AUTOSAR XML (schema 4-2-2)
package /DBC_SysDesc_Can_Network/Pkg_Cluster
  can cluster Can_NCluster: baudrate=500000, protocol-name=CAN
    can physical channel Can_NCluster_Channel: comm-connectors=Conn_CANNODE_0_BMS
      frame TMR_3: id 0x328, to BMS, frame-length=8, can-addressing-mode=STANDARD, can-frame-rx-behavior=ANY
        carries pdu TMR_3: packing-byte-order=big-endian, start-position=7, update-indication-bit-position=-1
        pdu TMR_3: length=8, transmission-mode-false-timing=cyclic-timing={time-offset=0.0, time-period=0.05}, transmission-mode-true-timing=cyclic-timing={time-offset=0.0, time-period=0.05}
          transmission-mode-conditions:
            {data-filter={data-filter-type=NEW-IS-WITHIN, max=1021, min=0, offset=0}, i-signal-in-i-pdu=TMR_VoltageHV}
            {data-filter={data-filter-type=NEW-IS-WITHIN, max=2044, min=0}, i-signal-in-i-pdu=TMR_CurrentHV}
          signal TMR_VoltageHV: start 12, 10 bit, big-endian, init-value=0, base-type=uint16, compu {raw=phys for phys 0..1021; unit V}, update-indication-bit-position=-1, to BMS  # HV voltage at the DC/AC converter"
          signal TMR_CurrentHV: start 7, 11 bit, big-endian, init-value=1023, base-type=uint16, compu {raw=phys+1023 for phys -1023..1021; unit Ampere}, update-indication-bit-position=-1, to BMS  # HV current at the DC/AC converter"
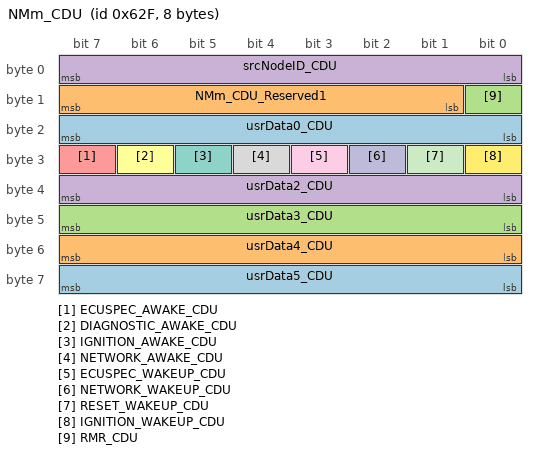
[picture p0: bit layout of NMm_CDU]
      frame NMm_CDU: id 0x62F, to BMS, frame-length=8, can-addressing-mode=STANDARD, can-frame-rx-behavior=ANY
        carries pdu NMm_CDU: packing-byte-order=big-endian, start-position=7, update-indication-bit-position=-1
        nm pdu NMm_CDU: length=8, nm-data-information=false, nm-vote-information=false
          signal usrData5_CDU: start 63, 8 bit, big-endian, init-value=0, base-type=uint8, compu {raw=phys for phys 0..255}, update-indication-bit-position=-1, to BMS
          signal usrData4_CDU: start 55, 8 bit, big-endian, init-value=0, base-type=uint8, compu {raw=phys for phys 0..255}, update-indication-bit-position=-1, to BMS
          signal usrData3_CDU: start 47, 8 bit, big-endian, init-value=0, base-type=uint8, compu {raw=phys for phys 0..255}, update-indication-bit-position=-1, to BMS
          signal usrData2_CDU: start 39, 8 bit, big-endian, init-value=0, base-type=uint8, compu {raw=phys for phys 0..255}, update-indication-bit-position=-1, to BMS
          signal ECUSPEC_AWAKE_CDU: start 31, 1 bit, big-endian, init-value=0, base-type=uint8, compu {raw=phys for phys 0..1, 0=INACTIVE, 1=ACTIVE}, update-indication-bit-position=-1, to BMS  # ECU keeps the network awake for ECU-define reasons for which communication is needed"
          signal DIAGNOSTIC_AWAKE_CDU: start 30, 1 bit, big-endian, init-value=0, base-type=uint8, compu {raw=phys for phys 0..1, 0=INACTIVE, 1=ACTIVE}, update-indication-bit-position=-1, to BMS  # ECU needs communication for diagnostic purpose and keeps network awake."
          signal IGNITION_AWAKE_CDU: start 29, 1 bit, big-endian, init-value=0, base-type=uint8, compu {raw=phys for phys 0..1, 0=INACTIVE, 1=ACTIVE}, update-indication-bit-position=-1, to BMS  # ECU can?t release communication because ignition (KL15) is turn on, or KLR is turned on"
          signal NETWORK_AWAKE_CDU: start 28, 1 bit, big-endian, init-value=0, base-type=uint8, compu {raw=phys for phys 0..1, 0=INACTIVE, 1=ACTIVE}, update-indication-bit-position=-1, to BMS  # ECU keeps the network awake due to the CAN message received from the network"
          signal ECUSPEC_WAKEUP_CDU: start 27, 1 bit, big-endian, init-value=0, base-type=uint8, compu {raw=phys for phys 0..1, 0=INACTIVE, 1=ACTIVE}, update-indication-bit-position=-1, to BMS  # ECU was in ??power off??, ??Bus Sleep??, ??Pre-pare Bus Sleep?? or ??Ready Sleep?? mode or ??awake?? and re-started by ECU specific reason (e.g. pressed Button, timer, etc.)"
          signal NETWORK_WAKEUP_CDU: start 26, 1 bit, big-endian, init-value=0, base-type=uint8, compu {raw=phys for phys 0..1, 0=INACTIVE, 1=ACTIVE}, update-indication-bit-position=-1, to BMS  # ECU was in ??Power off??, ??Bus Sleep??, ??Pre-pare Bus Sleep?? or ??Ready Sleep?? Mode and then re-started by a network communication."
          signal RESET_WAKEUP_CDU: start 25, 1 bit, big-endian, init-value=0, base-type=uint8, compu {raw=phys for phys 0..1, 0=INACTIVE, 1=ACTIVE}, update-indication-bit-position=-1, to BMS  # If ECU was already awake, in ??Prepare Bus Sleep?? or ??Ready Sleep?? mode and re-started by an internal or an external reset."
          signal IGNITION_WAKEUP_CDU: start 24, 1 bit, big-endian, init-value=0, base-type=uint8, compu {raw=phys for phys 0..1, 0=INACTIVE, 1=ACTIVE}, update-indication-bit-position=-1, to BMS  # ECU was ??power off?? or ??Bus sleep?? mode and started by ignition switch"
          signal usrData0_CDU: start 23, 8 bit, big-endian, init-value=0, base-type=uint8, compu-method=CompuMethod_usrData0_CDU, update-indication-bit-position=-1, to BMS
          signal NMm_CDU_Reserved1: start 15, 7 bit, big-endian, init-value=0, base-type=uint8, compu {raw=phys for phys 0..127}, update-indication-bit-position=-1, to BMS
          signal RMR_CDU: start 8, 1 bit, big-endian, init-value=0, base-type=uint8, compu {raw=phys for phys 0..1, 0=INACTIVE, 1=ACTIVE}, update-indication-bit-position=-1, to BMS  # If set to 1 to force the network management of all other nodes on the bus into the re-peat message state."
          signal srcNodeID_CDU: start 7, 8 bit, big-endian, init-value=2, base-type=uint8, compu {raw=phys for phys 0..255}, update-indication-bit-position=-1, to BMS
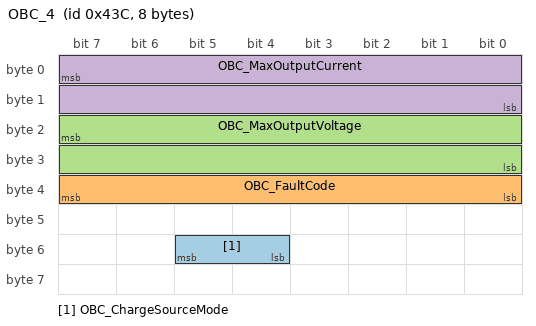
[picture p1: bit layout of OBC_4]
      frame OBC_4: id 0x43C, to BMS, frame-length=8, can-addressing-mode=STANDARD, can-frame-rx-behavior=ANY
        carries pdu OBC_4: packing-byte-order=big-endian, start-position=7, update-indication-bit-position=-1
        pdu OBC_4: length=8, transmission-mode-false-timing=cyclic-timing={time-offset=0.0, time-period=0.1}, transmission-mode-true-timing=cyclic-timing={time-offset=0.0, time-period=0.1}
          transmission-mode-conditions:
            {data-filter={data-filter-type=ALWAYS, max=0, min=0, offset=0}, i-signal-in-i-pdu=OBC_ChargeSourceMode}
            {data-filter={data-filter-type=ALWAYS, max=255, min=0, offset=0}, i-signal-in-i-pdu=OBC_FaultCode}
            {data-filter={data-filter-type=NEW-IS-WITHIN, max=20000, min=0, offset=0}, i-signal-in-i-pdu=OBC_MaxOutputVoltage}
            {data-filter={data-filter-type=NEW-IS-WITHIN, max=8000, min=0, offset=0}, i-signal-in-i-pdu=OBC_MaxOutputCurrent}
          signal OBC_ChargeSourceMode: start 53, 2 bit, big-endian, init-value=0, base-type=uint8, compu-method=CompuMethod_OBC_ChargeSourceMode, update-indication-bit-position=-1, to BMS  # Charge Source Mode"
          signal OBC_FaultCode: start 39, 8 bit, big-endian, init-value=0, base-type=uint8, compu {raw=phys for phys 0..255}, update-indication-bit-position=-1, to BMS  # OBC fault matrix"
          signal OBC_MaxOutputVoltage: start 23, 16 bit, big-endian, init-value=0, base-type=uint16, compu {raw=phys*20 for phys 0..1000; unit V}, update-indication-bit-position=-1, to BMS  # OBC maximum output current"
          signal OBC_MaxOutputCurrent: start 7, 16 bit, big-endian, init-value=0, base-type=uint16, compu {raw=phys*20 for phys 0..400; unit Ampere}, update-indication-bit-position=-1, to BMS  # OBC maximum output voltage"
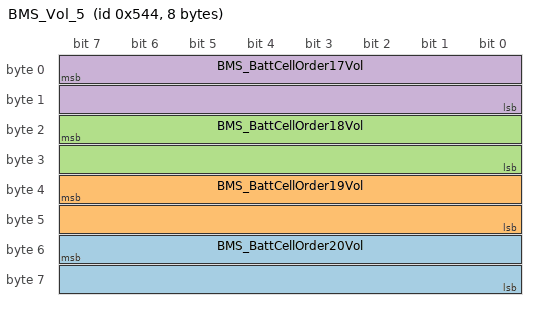
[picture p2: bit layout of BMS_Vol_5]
      frame BMS_Vol_5: id 0x544, from BMS, frame-length=8, can-addressing-mode=STANDARD
        carries pdu BMS_Vol_5: packing-byte-order=big-endian, start-position=7, update-indication-bit-position=-1
        pdu BMS_Vol_5: length=8, transmission-mode-false-timing=cyclic-timing={time-offset=0.0, time-period=1.0}, transmission-mode-true-timing=cyclic-timing={time-offset=0.0, time-period=1.0}
          transmission-mode-conditions:
            {data-filter={data-filter-type=NEW-IS-WITHIN, max=5000, min=0, offset=0}, i-signal-in-i-pdu=BMS_BattCellOrder20Vol}
            {data-filter={data-filter-type=NEW-IS-WITHIN, max=5000, min=0, offset=0}, i-signal-in-i-pdu=BMS_BattCellOrder19Vol}
            {data-filter={data-filter-type=NEW-IS-WITHIN, max=5000, min=0, offset=0}, i-signal-in-i-pdu=BMS_BattCellOrder18Vol}
            {data-filter={data-filter-type=NEW-IS-WITHIN, max=5000, min=0, offset=0}, i-signal-in-i-pdu=BMS_BattCellOrder17Vol}
          signal BMS_BattCellOrder20Vol: start 55, 16 bit, big-endian, init-value=0, base-type=uint16, compu {raw=phys for phys 0..5000; unit mV}, update-indication-bit-position=-1  # Battery Cell voltage Order20"
          signal BMS_BattCellOrder19Vol: start 39, 16 bit, big-endian, init-value=0, base-type=uint16, compu {raw=phys for phys 0..5000; unit mV}, update-indication-bit-position=-1  # Battery Cell voltage Order19"
          signal BMS_BattCellOrder18Vol: start 23, 16 bit, big-endian, init-value=0, base-type=uint16, compu {raw=phys for phys 0..5000; unit mV}, update-indication-bit-position=-1  # Battery Cell voltage Order18"
          signal BMS_BattCellOrder17Vol: start 7, 16 bit, big-endian, init-value=0, base-type=uint16, compu {raw=phys for phys 0..5000; unit mV}, update-indication-bit-position=-1  # Battery Cell voltage Order17"
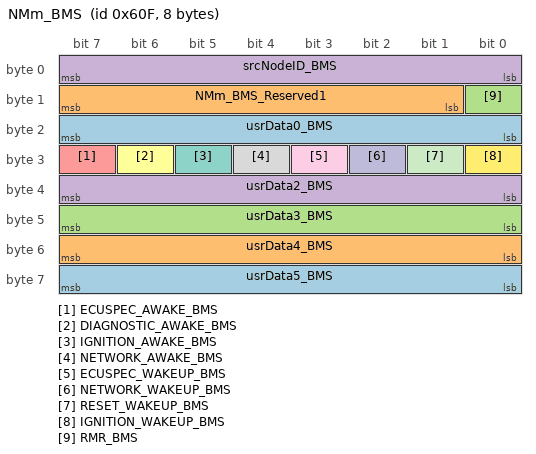
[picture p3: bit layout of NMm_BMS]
      frame NMm_BMS: id 0x60F, from BMS, frame-length=8, can-addressing-mode=STANDARD
        carries pdu NMm_BMS: packing-byte-order=big-endian, start-position=7, update-indication-bit-position=-1
        nm pdu NMm_BMS: length=8, nm-data-information=false, nm-vote-information=false
          signal usrData5_BMS: start 63, 8 bit, big-endian, init-value=0, base-type=uint8, compu {raw=phys for phys 0..255}, update-indication-bit-position=-1
          signal usrData4_BMS: start 55, 8 bit, big-endian, init-value=0, base-type=uint8, compu {raw=phys for phys 0..255}, update-indication-bit-position=-1
          signal usrData3_BMS: start 47, 8 bit, big-endian, init-value=0, base-type=uint8, compu {raw=phys for phys 0..255}, update-indication-bit-position=-1
          signal usrData2_BMS: start 39, 8 bit, big-endian, init-value=0, base-type=uint8, compu {raw=phys for phys 0..255}, update-indication-bit-position=-1
          signal ECUSPEC_AWAKE_BMS: start 31, 1 bit, big-endian, init-value=0, base-type=uint8, compu {raw=phys for phys 0..1, 0=INACTIVE, 1=ACTIVE}, update-indication-bit-position=-1  # ECU keeps the network awake for ECU-define reasons for which communication is needed"
          signal DIAGNOSTIC_AWAKE_BMS: start 30, 1 bit, big-endian, init-value=0, base-type=uint8, compu {raw=phys for phys 0..1, 0=INACTIVE, 1=ACTIVE}, update-indication-bit-position=-1  # ECU needs communication for diagnostic purpose and keeps network awake."
          signal IGNITION_AWAKE_BMS: start 29, 1 bit, big-endian, init-value=0, base-type=uint8, compu {raw=phys for phys 0..1, 0=INACTIVE, 1=ACTIVE}, update-indication-bit-position=-1  # ECU can?t release communication because ignition (KL15) is turn on, or KLR is turned on"
          signal NETWORK_AWAKE_BMS: start 28, 1 bit, big-endian, init-value=0, base-type=uint8, compu {raw=phys for phys 0..1, 0=INACTIVE, 1=ACTIVE}, update-indication-bit-position=-1  # ECU keeps the network awake due to the CAN message received from the network"
          signal ECUSPEC_WAKEUP_BMS: start 27, 1 bit, big-endian, init-value=0, base-type=uint8, compu {raw=phys for phys 0..1, 0=INACTIVE, 1=ACTIVE}, update-indication-bit-position=-1  # ECU was in ??power off??, ??Bus Sleep??, ??Pre-pare Bus Sleep?? or ??Ready Sleep?? mode or ??awake?? and re-started by ECU specific reason (e.g. pressed Button, timer, etc.)"
          signal NETWORK_WAKEUP_BMS: start 26, 1 bit, big-endian, init-value=0, base-type=uint8, compu {raw=phys for phys 0..1, 0=INACTIVE, 1=ACTIVE}, update-indication-bit-position=-1  # ECU was in ??Power off??, ??Bus Sleep??, ??Pre-pare Bus Sleep?? or ??Ready Sleep?? Mode and then re-started by a network communication."
          signal RESET_WAKEUP_BMS: start 25, 1 bit, big-endian, init-value=0, base-type=uint8, compu {raw=phys for phys 0..1, 0=INACTIVE, 1=ACTIVE}, update-indication-bit-position=-1  # If ECU was already awake, in ??Prepare Bus Sleep?? or ??Ready Sleep?? mode and re-started by an internal or an external reset."
          signal IGNITION_WAKEUP_BMS: start 24, 1 bit, big-endian, init-value=0, base-type=uint8, compu {raw=phys for phys 0..1, 0=INACTIVE, 1=ACTIVE}, update-indication-bit-position=-1  # ECU was ??power off?? or ??Bus sleep?? mode and started by ignition switch"
          signal usrData0_BMS: start 23, 8 bit, big-endian, init-value=0, base-type=uint8, compu-method=CompuMethod_usrData0_BMS, update-indication-bit-position=-1
          signal NMm_BMS_Reserved1: start 15, 7 bit, big-endian, init-value=0, base-type=uint8, compu {raw=phys for phys 0..127}, update-indication-bit-position=-1
          signal RMR_BMS: start 8, 1 bit, big-endian, init-value=0, base-type=uint8, compu {raw=phys for phys 0..1, 0=INACTIVE, 1=ACTIVE}, update-indication-bit-position=-1  # If set to 1 to force the network management of all other nodes on the bus into the re-peat message state."
          signal srcNodeID_BMS: start 7, 8 bit, big-endian, init-value=2, base-type=uint8, compu {raw=phys for phys 0..255}, update-indication-bit-position=-1
package /DBC_SysDesc_Can_Network/Pkg_Nm
  nm config NmConfig_0
    can nm cluster CanNmCluster_0: communication-cluster=Can_NCluster, nm-channel-id=1, nm-channel-sleep-master=false, nm-synchronizing-network=false, nm-busload-reduction-active=false, nm-car-wake-up-filter-enabled=false, nm-car-wake-up-rx-enabled=false, nm-channel-active=false
      can nm node CanNmMode_BMS_CANNODE_0: controller=CANNODE_0, nm-if-ecu=NmEcu_BMS, nm-node-id=1, nm-passive-mode-enabled=false, rx-nm-pdu=NMm_CDU, tx-nm-pdu=NMm_BMS, nm-range-config={lower-can-id=1551, upper-can-id=1583}
    nm-if-ecus:
      nm ecu NmEcu_BMS:
        bus-specific-nm-ecu=can-nm-ecu=nm-repeat-msg-indication-enabled=false
        ecu-instance=BMS
        nm-bus-synchronization-enabled=false
        nm-com-control-enabled=false
        nm-coordinator={index=0, nm-active-coordinator=true, nm-node=CanNmMode_BMS_CANNODE_0, nm-shutdown-delay-timer=0.0}
        nm-multiple-channels-enabled=false
        nm-node-detection-enabled=false
        nm-node-id-enabled=false
        nm-passive-mode-enabled=false
        nm-pdu-rx-indication-enabled=false
        nm-remote-sleep-ind-enabled=false
        nm-repeat-msg-ind-enabled=false
        nm-state-change-ind-enabled=false
        nm-user-data-enabled=false
package /DBC_SysDesc_Can_Network/Pkg_Ecu
  ecu instance BMS: com-configuration-gw-time-base=0.005, com-configuration-rx-time-base=0.01, com-configuration-tx-time-base=0.01, sleep-mode-supported=false, wake-up-over-bus-supported=false
    can communication controller CANNODE_0: can-controller-attributes=can-controller-configuration={prop-seg=2, sync-jump-width=1, time-seg-1=12, time-seg-2=5}
    can communication connector Conn_CANNODE_0_BMS: comm-controller=CANNODE_0
package /DBC_SysDesc_Can_Network/Pkg_CompuMethod
  compu method CompuMethod_usrData0_BMS: raw=phys for phys 0..255, 230=NOTUSED, 231=NOTUSED, 110=NOTUSED, 232=NOTUSED, 111=NOTUSED, 233=NOTUSED, 112=NOTUSED, 234=NOTUSED, 113=NOTUSED, 235=NOTUSED, 114=NOTUSED, 236=NOTUSED, 115=NOTUSED, 237=NOTUSED, 116=NOTUSED, 238=NOTUSED, 117=NOTUSED, 239=NOTUSED, 118=NOTUSED, 119=NOTUSED, 10..19=NOTUSED, 240=NOTUSED, 241=NOTUSED, 120=NOTUSED, 242=NOTUSED, 121=NOTUSED, 0=USERDATAFORCURRENTVEHICLE, 243=NOTUSED, 122=NOTUSED, 1=NOTUSED, 244=NOTUSED, 123=NOTUSED, 2=NOTUSED, 245=NOTUSED, 124=NOTUSED, 3=NOTUSED, 246=NOTUSED, 125=NOTUSED, 4=NOTUSED, 247=NOTUSED, 126=NOTUSED, 5=NOTUSED, 248=NOTUSED, 127=NOTUSED, 6=NOTUSED, 249=NOTUSED, 128=NOTUSED, 7=NOTUSED, 129=NOTUSED, 8=NOTUSED, 9=NOTUSED, 20..29=NOTUSED, 250=NOTUSED, 251=NOTUSED, 130=NOTUSED, 252=NOTUSED, 131=NOTUSED, 253=NOTUSED, 132=NOTUSED, 254=NOTUSED, 133=NOTUSED, 134=NOTUSED, 255=USERDATANOTUSED, 135..139=NOTUSED, 30..39=NOTUSED, 140..149=NOTUSED, 40..49=NOTUSED, 150..159=NOTUSED, 50..59=NOTUSED, 160..169=NOTUSED, 60..69=NOTUSED, 170..179=NOTUSED, 70..79=NOTUSED, 180..189=NOTUSED, 80..89=NOTUSED, 190..199=NOTUSED, 90..99=NOTUSED, 200..221=NOTUSED, 100=NOTUSED, 222=NOTUSED, 101=NOTUSED, 223=NOTUSED, 102=NOTUSED, 224=NOTUSED, 103=NOTUSED, 225=NOTUSED, 104=NOTUSED, 226=NOTUSED, 105=NOTUSED, 227=NOTUSED, 106=NOTUSED, 228=NOTUSED, 107=NOTUSED, 229=NOTUSED, 108=NOTUSED, 109=NOTUSED
  compu method CompuMethod_usrData0_CDU: raw=phys for phys 0..255, 230=NOTUSED, 231=NOTUSED, 110=NOTUSED, 232=NOTUSED, 111=NOTUSED, 233=NOTUSED, 112=NOTUSED, 234=NOTUSED, 113=NOTUSED, 235=NOTUSED, 114=NOTUSED, 236=NOTUSED, 115=NOTUSED, 237=NOTUSED, 116=NOTUSED, 238=NOTUSED, 117=NOTUSED, 239=NOTUSED, 118=NOTUSED, 119=NOTUSED, 10..19=NOTUSED, 240=NOTUSED, 241=NOTUSED, 120=NOTUSED, 242=NOTUSED, 121=NOTUSED, 0=USERDATAFORCURRENTVEHICLE, 243=NOTUSED, 122=NOTUSED, 1=NOTUSED, 244=NOTUSED, 123=NOTUSED, 2=NOTUSED, 245=NOTUSED, 124=NOTUSED, 3=NOTUSED, 246=NOTUSED, 125=NOTUSED, 4=NOTUSED, 247=NOTUSED, 126=NOTUSED, 5=NOTUSED, 248=NOTUSED, 127=NOTUSED, 6=NOTUSED, 249=NOTUSED, 128=NOTUSED, 7=NOTUSED, 129=NOTUSED, 8=NOTUSED, 9=NOTUSED, 20..29=NOTUSED, 250=NOTUSED, 251=NOTUSED, 130=NOTUSED, 252=NOTUSED, 131=NOTUSED, 253=NOTUSED, 132=NOTUSED, 254=NOTUSED, 133=NOTUSED, 134=NOTUSED, 255=USERDATANOTUSED, 135..139=NOTUSED, 30..39=NOTUSED, 140..149=NOTUSED, 40..49=NOTUSED, 150..159=NOTUSED, 50..59=NOTUSED, 160..169=NOTUSED, 60..69=NOTUSED, 170..179=NOTUSED, 70..79=NOTUSED, 180..189=NOTUSED, 80..89=NOTUSED, 190..199=NOTUSED, 90..99=NOTUSED, 200..221=NOTUSED, 100=NOTUSED, 222=NOTUSED, 101=NOTUSED, 223=NOTUSED, 102=NOTUSED, 224=NOTUSED, 103=NOTUSED, 225=NOTUSED, 104=NOTUSED, 226=NOTUSED, 105=NOTUSED, 227=NOTUSED, 106=NOTUSED, 228=NOTUSED, 107=NOTUSED, 229=NOTUSED, 108=NOTUSED, 109=NOTUSED
  compu method CompuMethod_OBC_ChargeSourceMode: raw=phys for phys 0, 0=NONE, 1=CONSTANTVOLTAGE, 2=CONSTANTCURRENT, 3=RESERVED
package /DBC_SysDesc_Can_Network/Pkg_Units
  unit mV
  unit V
  unit Ampere
